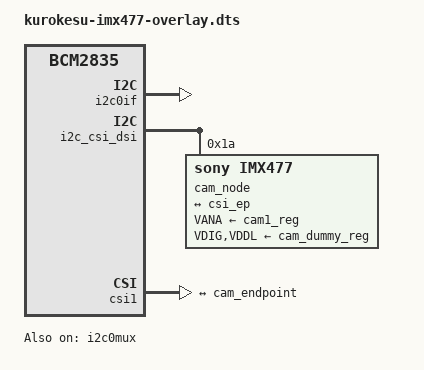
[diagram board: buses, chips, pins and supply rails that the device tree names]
// SPDX-License-Identifier: GPL-2.0-only
// Definitions for Kurokesu IMX477 camera module on VC I2C bus
/dts-v1/;
/plugin/;

/{
	compatible = "brcm,bcm2835";

	fragment@0 {
		target = <&i2c0if>;
		__overlay__ {
			status = "okay";
		};
	};

	clk_frag: fragment@1 {
		target = <&cam1_clk>;
		__overlay__ {
			status = "okay";
			clock-frequency = <24000000>;
		};
	};

	fragment@2 {
		target = <&i2c0mux>;
		__overlay__ {
			status = "okay";
		};
	};

	reg_frag: fragment@3 {
		target = <&cam1_reg>;
		__overlay__ {
			startup-delay-us = <300000>;
		};
	};

	fragment@4 {
		target = <&cam_endpoint>;
		__overlay__ {
			data-lanes = <1 2>;
		};
	};

	fragment@5 {
		target = <&cam_endpoint>;
		__dormant__ {
			data-lanes = <1 2 3 4>;
		};
	};

	fragment@6 {
		target = <&csi_ep>;
		__overlay__ {
			data-lanes = <1 2>;
		};
	};

	fragment@7 {
		target = <&csi_ep>;
		__dormant__ {
			data-lanes = <1 2 3 4>;
		};
	};

	reg_alwayson_frag: fragment@99 {
		target = <&cam1_reg>;
		__dormant__ {
			regulator-always-on;
		};
	};

	i2c_frag: fragment@100 {
		target = <&i2c_csi_dsi>;
		__overlay__ {
			#address-cells = <1>;
			#size-cells = <0>;
			status = "okay";

			cam_node: imx477@1a {
				compatible = "sony,imx477";
				reg = <0x1a>;
				status = "okay";

				clocks = <&cam1_clk>;
				clock-names = "xclk";

				VANA-supply = <&cam1_reg>;	/* 2.8v */
				VDIG-supply = <&cam_dummy_reg>;	/* 1.05v */
				VDDL-supply = <&cam_dummy_reg>;	/* 1.8v */

				rotation = <0>;
				orientation = <2>;

				port {
					cam_endpoint: endpoint {
						remote-endpoint = <&csi_ep>;
						clock-lanes = <0>;
						clock-noncontinuous;
						link-frequencies =
							/bits/ 64 <450000000>;
					};
				};
			};
		};
	};

	csi_frag: fragment@101 {
		target = <&csi1>;
		csi: __overlay__ {
			status = "okay";

			port {
				csi_ep: endpoint {
					remote-endpoint = <&cam_endpoint>;
					clock-lanes = <0>;
					clock-noncontinuous;
				};
			};
		};
	};

	fragment@102 {
		target = <&csi>;
		__dormant__ {
			compatible = "brcm,bcm2835-unicam-legacy";
		};
	};

	__overrides__ {
		4lane = <0>, "-4+5-6+7";
		rotation = <&cam_node>,"rotation:0";
		orientation = <&cam_node>,"orientation:0";
		media-controller = <0>,"!102";
		cam0 = <&i2c_frag>, "target:0=",<&i2c_csi_dsi0>,
		       <&csi_frag>, "target:0=",<&csi0>,
		       <&clk_frag>, "target:0=",<&cam0_clk>,
		       <&reg_frag>, "target:0=",<&cam0_reg>,
		       <&reg_alwayson_frag>, "target:0=",<&cam0_reg>,
		       <&cam_node>, "clocks:0=",<&cam0_clk>,
		       <&cam_node>, "VANA-supply:0=",<&cam0_reg>;
		always-on = <0>, "+99";
		link-frequency = <&cam_endpoint>,"link-frequencies#0";
		sync-sink = <&cam_node>,"trigger-mode:0=2";
		sync-source = <&cam_node>,"trigger-mode:0=1";
	};
};
